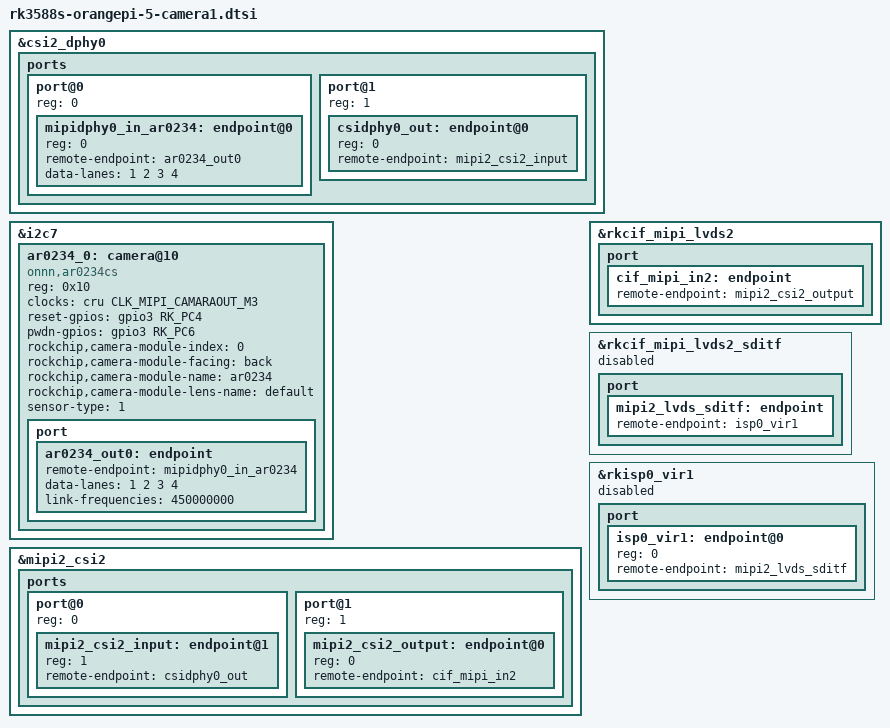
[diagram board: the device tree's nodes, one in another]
// SPDX-License-Identifier: (GPL-2.0+ OR MIT)
/*
 * Copyright (c) 2021 Rockchip Electronics Co., Ltd.
 *
 */

&csi2_dphy0 {
    status = "okay";
    ports {
        #address-cells = <1>;
        #size-cells = <0>;

        port@0 {
            reg = <0>;
            #address-cells = <1>;
            #size-cells = <0>;

            mipidphy0_in_ar0234: endpoint@0 {
                reg = <0>;
                remote-endpoint = <&ar0234_out0>;
                data-lanes = <1 2 3 4>;
            };
        };

        port@1 {
            reg = <1>;
            #address-cells = <1>;
            #size-cells = <0>;

            csidphy0_out: endpoint@0 {
                reg = <0>;
                remote-endpoint = <&mipi2_csi2_input>;
            };
        };
    };
};

&i2c7 {
	status = "okay";

	ar0234_0: camera@10 {
		compatible = "onnn,ar0234cs";
		status = "okay";
		reg = <0x10>;

		clocks = <&cru CLK_MIPI_CAMARAOUT_M3>;
		clock-names = "xvclk";

		reset-gpios = <&gpio3 RK_PC4 GPIO_ACTIVE_HIGH>;
		pwdn-gpios = <&gpio3 RK_PC6 GPIO_ACTIVE_HIGH>;
		rockchip,camera-module-index = <0>;
		rockchip,camera-module-facing = "back";
		rockchip,camera-module-name = "ar0234";
		rockchip,camera-module-lens-name = "default";

		/* 黑白传感器 */
		sensor-type = <1>;

		port {
			ar0234_out0: endpoint {
				remote-endpoint = <&mipidphy0_in_ar0234>;
				data-lanes = <1 2 3 4>;
				link-frequencies = /bits/ 64 <450000000>;
			};
		};
	};
};

&mipi2_csi2 {
	status = "okay";
	ports {
		#address-cells = <1>;
		#size-cells = <0>;
		port@0 {
			reg = <0>;
			#address-cells = <1>;
			#size-cells = <0>;
			mipi2_csi2_input: endpoint@1 {
				reg = <1>;
				remote-endpoint = <&csidphy0_out>;
			};
		};
		port@1 {
			reg = <1>;
			#address-cells = <1>;
			#size-cells = <0>;
			mipi2_csi2_output: endpoint@0 {
				reg = <0>;
				remote-endpoint = <&cif_mipi_in2>;
			};
		};
	};
};

&rkcif_mipi_lvds2 {
	status = "okay";
	port {
		cif_mipi_in2: endpoint {
			remote-endpoint = <&mipi2_csi2_output>;
		};
	};
};

&rkcif_mipi_lvds2_sditf {
	status = "disabled";
	port {
		mipi2_lvds_sditf: endpoint {
			remote-endpoint = <&isp0_vir1>;
		};
	};
};

&rkisp0_vir1 {
	status = "disabled";
	port {
		#address-cells = <1>;
		#size-cells = <0>;
		isp0_vir1: endpoint@0 {
			reg = <0>;
			remote-endpoint = <&mipi2_lvds_sditf>;
		};
	};
};
